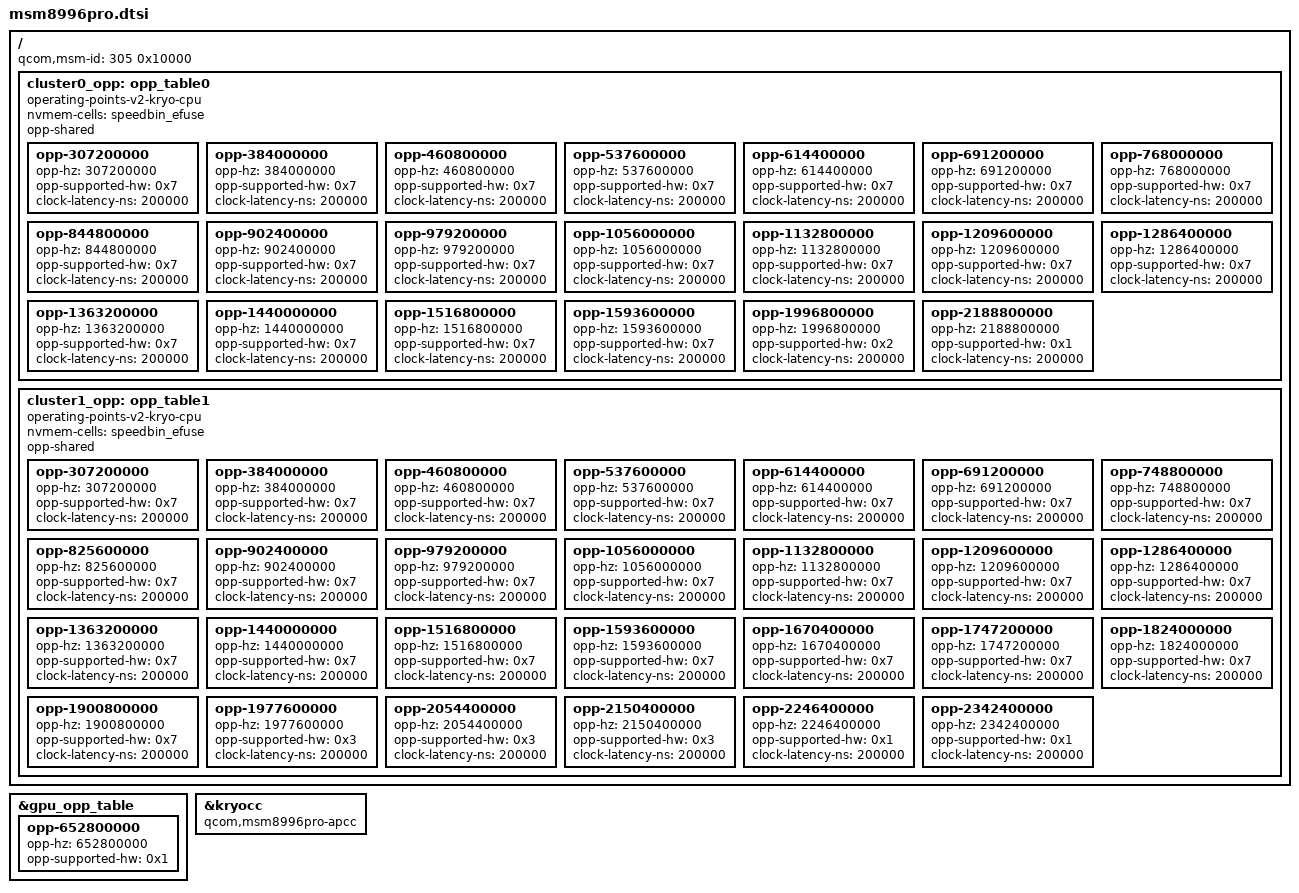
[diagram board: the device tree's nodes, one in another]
// SPDX-License-Identifier: BSD-3-Clause
/*
 * Copyright (c) 2021, Yassine Oudjana <y.oudjana@protonmail.com>
 */

#include "msm8996.dtsi"

/*
 * MSM8996 Pro (also known as MSM8996SG) is a revision of MSM8996 with
 * different CPU, CBF and GPU frequencies as well as CPR parameters.
 */
/delete-node/ &cluster0_opp;
/delete-node/ &cluster1_opp;

/ {
	qcom,msm-id = <305 0x10000>;

	cluster0_opp: opp_table0 {
		compatible = "operating-points-v2-kryo-cpu";
		nvmem-cells = <&speedbin_efuse>;
		opp-shared;

		opp-307200000 {
			opp-hz = /bits/ 64 <307200000>;
			opp-supported-hw = <0x7>;
			clock-latency-ns = <200000>;
		};
		opp-384000000 {
			opp-hz = /bits/ 64 <384000000>;
			opp-supported-hw = <0x7>;
			clock-latency-ns = <200000>;
		};
		opp-460800000 {
			opp-hz = /bits/ 64 <460800000>;
			opp-supported-hw = <0x7>;
			clock-latency-ns = <200000>;
		};
		opp-537600000 {
			opp-hz = /bits/ 64 <537600000>;
			opp-supported-hw = <0x7>;
			clock-latency-ns = <200000>;
		};
		opp-614400000 {
			opp-hz = /bits/ 64 <614400000>;
			opp-supported-hw = <0x7>;
			clock-latency-ns = <200000>;
		};
		opp-691200000 {
			opp-hz = /bits/ 64 <691200000>;
			opp-supported-hw = <0x7>;
			clock-latency-ns = <200000>;
		};
		opp-768000000 {
			opp-hz = /bits/ 64 <768000000>;
			opp-supported-hw = <0x7>;
			clock-latency-ns = <200000>;
		};
		opp-844800000 {
			opp-hz = /bits/ 64 <844800000>;
			opp-supported-hw = <0x7>;
			clock-latency-ns = <200000>;
		};
		opp-902400000 {
			opp-hz = /bits/ 64 <902400000>;
			opp-supported-hw = <0x7>;
			clock-latency-ns = <200000>;
		};
		opp-979200000 {
			opp-hz = /bits/ 64 <979200000>;
			opp-supported-hw = <0x7>;
			clock-latency-ns = <200000>;
		};
		opp-1056000000 {
			opp-hz = /bits/ 64 <1056000000>;
			opp-supported-hw = <0x7>;
			clock-latency-ns = <200000>;
		};
		opp-1132800000 {
			opp-hz = /bits/ 64 <1132800000>;
			opp-supported-hw = <0x7>;
			clock-latency-ns = <200000>;
		};
		opp-1209600000 {
			opp-hz = /bits/ 64 <1209600000>;
			opp-supported-hw = <0x7>;
			clock-latency-ns = <200000>;
		};
		opp-1286400000 {
			opp-hz = /bits/ 64 <1286400000>;
			opp-supported-hw = <0x7>;
			clock-latency-ns = <200000>;
		};
		opp-1363200000 {
			opp-hz = /bits/ 64 <1363200000>;
			opp-supported-hw = <0x7>;
			clock-latency-ns = <200000>;
		};
		opp-1440000000 {
			opp-hz = /bits/ 64 <1440000000>;
			opp-supported-hw = <0x7>;
			clock-latency-ns = <200000>;
		};
		opp-1516800000 {
			opp-hz = /bits/ 64 <1516800000>;
			opp-supported-hw = <0x7>;
			clock-latency-ns = <200000>;
		};
		opp-1593600000 {
			opp-hz = /bits/ 64 <1593600000>;
			opp-supported-hw = <0x7>;
			clock-latency-ns = <200000>;
		};
		opp-1996800000 {
			opp-hz = /bits/ 64 <1996800000>;
			opp-supported-hw = <0x2>;
			clock-latency-ns = <200000>;
		};
		opp-2188800000 {
			opp-hz = /bits/ 64 <2188800000>;
			opp-supported-hw = <0x1>;
			clock-latency-ns = <200000>;
		};
	};

	cluster1_opp: opp_table1 {
		compatible = "operating-points-v2-kryo-cpu";
		nvmem-cells = <&speedbin_efuse>;
		opp-shared;

		opp-307200000 {
			opp-hz = /bits/ 64 <307200000>;
			opp-supported-hw = <0x7>;
			clock-latency-ns = <200000>;
		};
		opp-384000000 {
			opp-hz = /bits/ 64 <384000000>;
			opp-supported-hw = <0x7>;
			clock-latency-ns = <200000>;
		};
		opp-460800000 {
			opp-hz = /bits/ 64 <460800000>;
			opp-supported-hw = <0x7>;
			clock-latency-ns = <200000>;
		};
		opp-537600000 {
			opp-hz = /bits/ 64 <537600000>;
			opp-supported-hw = <0x7>;
			clock-latency-ns = <200000>;
		};
		opp-614400000 {
			opp-hz = /bits/ 64 <614400000>;
			opp-supported-hw = <0x7>;
			clock-latency-ns = <200000>;
		};
		opp-691200000 {
			opp-hz = /bits/ 64 <691200000>;
			opp-supported-hw = <0x7>;
			clock-latency-ns = <200000>;
		};
		opp-748800000 {
			opp-hz = /bits/ 64 <748800000>;
			opp-supported-hw = <0x7>;
			clock-latency-ns = <200000>;
		};
		opp-825600000 {
			opp-hz = /bits/ 64 <825600000>;
			opp-supported-hw = <0x7>;
			clock-latency-ns = <200000>;
		};
		opp-902400000 {
			opp-hz = /bits/ 64 <902400000>;
			opp-supported-hw = <0x7>;
			clock-latency-ns = <200000>;
		};
		opp-979200000 {
			opp-hz = /bits/ 64 <979200000>;
			opp-supported-hw = <0x7>;
			clock-latency-ns = <200000>;
		};
		opp-1056000000 {
			opp-hz = /bits/ 64 <1056000000>;
			opp-supported-hw = <0x7>;
			clock-latency-ns = <200000>;
		};
		opp-1132800000 {
			opp-hz = /bits/ 64 <1132800000>;
			opp-supported-hw = <0x7>;
			clock-latency-ns = <200000>;
		};
		opp-1209600000 {
			opp-hz = /bits/ 64 <1209600000>;
			opp-supported-hw = <0x7>;
			clock-latency-ns = <200000>;
		};
		opp-1286400000 {
			opp-hz = /bits/ 64 <1286400000>;
			opp-supported-hw = <0x7>;
			clock-latency-ns = <200000>;
		};
		opp-1363200000 {
			opp-hz = /bits/ 64 <1363200000>;
			opp-supported-hw = <0x7>;
			clock-latency-ns = <200000>;
		};
		opp-1440000000 {
			opp-hz = /bits/ 64 <1440000000>;
			opp-supported-hw = <0x7>;
			clock-latency-ns = <200000>;
		};
		opp-1516800000 {
			opp-hz = /bits/ 64 <1516800000>;
			opp-supported-hw = <0x7>;
			clock-latency-ns = <200000>;
		};
		opp-1593600000 {
			opp-hz = /bits/ 64 <1593600000>;
			opp-supported-hw = <0x7>;
			clock-latency-ns = <200000>;
		};
		opp-1670400000 {
			opp-hz = /bits/ 64 <1670400000>;
			opp-supported-hw = <0x7>;
			clock-latency-ns = <200000>;
		};
		opp-1747200000 {
			opp-hz = /bits/ 64 <1747200000>;
			opp-supported-hw = <0x7>;
			clock-latency-ns = <200000>;
		};
		opp-1824000000 {
			opp-hz = /bits/ 64 <1824000000>;
			opp-supported-hw = <0x7>;
			clock-latency-ns = <200000>;
		};
		opp-1900800000 {
			opp-hz = /bits/ 64 <1900800000>;
			opp-supported-hw = <0x7>;
			clock-latency-ns = <200000>;
		};
		opp-1977600000 {
			opp-hz = /bits/ 64 <1977600000>;
			opp-supported-hw = <0x3>;
			clock-latency-ns = <200000>;
		};
		opp-2054400000 {
			opp-hz = /bits/ 64 <2054400000>;
			opp-supported-hw = <0x3>;
			clock-latency-ns = <200000>;
		};
		opp-2150400000 {
			opp-hz = /bits/ 64 <2150400000>;
			opp-supported-hw = <0x3>;
			clock-latency-ns = <200000>;
		};
		opp-2246400000 {
			opp-hz = /bits/ 64 <2246400000>;
			opp-supported-hw = <0x1>;
			clock-latency-ns = <200000>;
		};
		opp-2342400000 {
			opp-hz = /bits/ 64 <2342400000>;
			opp-supported-hw = <0x1>;
			clock-latency-ns = <200000>;
		};
	};
};

&gpu_opp_table {
	/*
	 * All MSM8996 GPU OPPs are available on MSM8996 Pro,
	 * in addition to one:
	 */
	opp-652800000 {
		opp-hz = /bits/ 64 <652800000>;
		opp-supported-hw = <0x1>;
	};
};

&kryocc {
	compatible = "qcom,msm8996pro-apcc";
};
